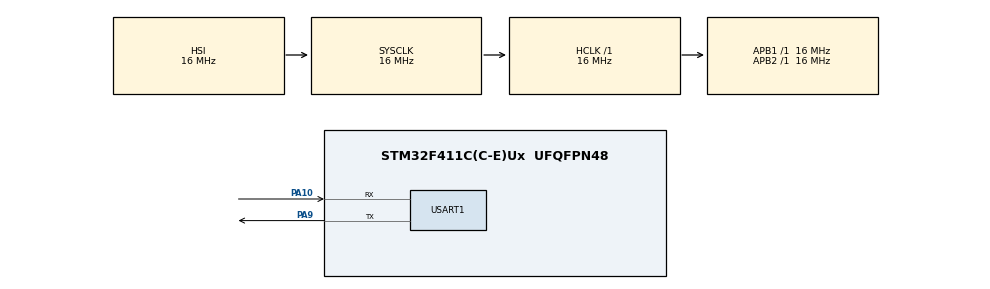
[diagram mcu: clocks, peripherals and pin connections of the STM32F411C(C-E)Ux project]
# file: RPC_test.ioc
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FREERTOS.Tasks01=defaultTask,24,128,StartDefaultTask,Default,NULL,Dynamic,NULL,NULL
Mcu.Family=STM32F4
Mcu.Name=STM32F411C(C-E)Ux
Mcu.Package=UFQFPN48
NVIC.PriorityGroup=NVIC_PRIORITYGROUP_4
NVIC.USART1_IRQn=true\:5\:0\:false\:false\:true\:true\:true\:true\:true
PA10.Mode=Asynchronous
PA10.Signal=USART1_RX
PA13.Mode=Serial_Wire
PA13.Signal=SYS_JTMS-SWDIO
PA14.Mode=Serial_Wire
PA14.Signal=SYS_JTCK-SWCLK
PA9.Mode=Asynchronous
PA9.Signal=USART1_TX
PC14-OSC32_IN.Mode=LSE-External-Oscillator
PC14-OSC32_IN.Signal=RCC_OSC32_IN
PC15-OSC32_OUT.Mode=LSE-External-Oscillator
PC15-OSC32_OUT.Signal=RCC_OSC32_OUT
PH0\ -\ OSC_IN.Mode=HSE-External-Oscillator
PH0\ -\ OSC_IN.Signal=RCC_OSC_IN
PH1\ -\ OSC_OUT.Mode=HSE-External-Oscillator
PH1\ -\ OSC_OUT.Signal=RCC_OSC_OUT
ProjectManager.HeapSize=0x200
ProjectManager.StackSize=0x400
ProjectManager.TargetToolchain=STM32CubeIDE
RCC.AHBFreq_Value=16000000
RCC.APB1Freq_Value=16000000
RCC.APB2Freq_Value=16000000
RCC.CortexFreq_Value=16000000
RCC.HSE_VALUE=25000000
RCC.HSI_VALUE=16000000
RCC.SYSCLKFreq_VALUE=16000000
RCC.VCOOutputFreq_Value=192000000
USART1.VirtualMode=VM_ASYNC
VP_FREERTOS_VS_CMSIS_V2.Mode=CMSIS_V2
board=custom

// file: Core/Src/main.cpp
/* USER CODE BEGIN Header */
/**
  ******************************************************************************
  * @file           : main.c
  * @brief          : Main program body
  ******************************************************************************
  * @attention
  *
  * Copyright (c) 2025 STMicroelectronics.
  * All rights reserved.
  *
  * This software is licensed under terms that can be found in the LICENSE file
  * in the root directory of this software component.
  * If no LICENSE file comes with this software, it is provided AS-IS.
  *
  ******************************************************************************
  */
/* USER CODE END Header */
#include "main.h"
#include "cmsis_os.h"
#include "RPC.h"
#include "stdio.h"
/* USER CODE BEGIN Includes */
class RPC rpc;
/* USER CODE END Includes */

/* USER CODE BEGIN PD */
#ifdef __cplusplus
extern "C" {
#endif

void AddBuffer(uint8_t data)
{
	rpc.AddBuffer(data);
}

#ifdef __cplusplus
}
#endif
/* USER CODE END PD */

UART_HandleTypeDef huart1;

/* Definitions for defaultTask */

void SystemClock_Config(void);
static void MX_GPIO_Init(void);
static void MX_USART1_UART_Init(void);
void StartDefaultTask(void *argument);

/* USER CODE BEGIN PFP */
void Echo(uint8_t* args, size_t argsLength, uint8_t*& response, size_t& responseLength) {
    response = (uint8_t*)pvPortMalloc(argsLength);
    memcpy(response, args, argsLength);
    responseLength = argsLength;
}

void EchoCallback(uint32_t id, uint8_t* data, size_t length, bool success) {
    if (success) printf("Ответ на запрос %lu получен! Длина: %d\n", id, length);
    else 		 printf("Ошибка в запросе %lu\n", id);

}
/* USER CODE END PFP */

int main(void)
{

  /* MCU Configuration--------------------------------------------------------*/

  /* Reset of all peripherals, Initializes the Flash interface and the Systick. */
  HAL_Init();

  /* Configure the system clock */
  SystemClock_Config();

  /* Initialize all configured peripherals */
  MX_GPIO_Init();
  MX_USART1_UART_Init();
  /* USER CODE BEGIN 2 */
  rpc.RegisterFunction("Echo", Echo);
  /* USER CODE END 2 */

  /* Init scheduler */
  osKernelInitialize();

  /* Create the thread(s) */
  /* creation of defaultTask */

  /* USER CODE BEGIN RTOS_THREADS */
  rpc.Start();
  /* USER CODE END RTOS_THREADS */

  uint8_t data[] = {0x01, 0x02, 0x03};

  rpc.SendRequest("Echo", data, sizeof(data), EchoCallback);

  /* Start scheduler */
  osKernelStart();

  /* We should never get here as control is now taken by the scheduler */

  /* Infinite loop */
  while (1)
  {

  }
}

void SystemClock_Config(void)
{
  RCC_OscInitTypeDef RCC_OscInitStruct = {0};
  RCC_ClkInitTypeDef RCC_ClkInitStruct = {0};

  /** Configure the main internal regulator output voltage
  */
  __HAL_RCC_PWR_CLK_ENABLE();
  __HAL_PWR_VOLTAGESCALING_CONFIG(PWR_REGULATOR_VOLTAGE_SCALE1);

  /** Initializes the RCC Oscillators according to the specified parameters
  * in the RCC_OscInitTypeDef structure.
  */
  RCC_OscInitStruct.OscillatorType = RCC_OSCILLATORTYPE_HSI;
  RCC_OscInitStruct.HSIState = RCC_HSI_ON;
  RCC_OscInitStruct.HSICalibrationValue = RCC_HSICALIBRATION_DEFAULT;
  RCC_OscInitStruct.PLL.PLLState = RCC_PLL_NONE;
  if (HAL_RCC_OscConfig(&RCC_OscInitStruct) != HAL_OK)
  {
    Error_Handler();
  }

  /** Initializes the CPU, AHB and APB buses clocks
  */
  RCC_ClkInitStruct.ClockType = RCC_CLOCKTYPE_HCLK|RCC_CLOCKTYPE_SYSCLK
                              |RCC_CLOCKTYPE_PCLK1|RCC_CLOCKTYPE_PCLK2;
  RCC_ClkInitStruct.SYSCLKSource = RCC_SYSCLKSOURCE_HSI;
  RCC_ClkInitStruct.AHBCLKDivider = RCC_SYSCLK_DIV1;
  RCC_ClkInitStruct.APB1CLKDivider = RCC_HCLK_DIV1;
  RCC_ClkInitStruct.APB2CLKDivider = RCC_HCLK_DIV1;

  if (HAL_RCC_ClockConfig(&RCC_ClkInitStruct, FLASH_LATENCY_0) != HAL_OK)
  {
    Error_Handler();
  }
}

static void MX_USART1_UART_Init(void)
{

  huart1.Instance = USART1;
  huart1.Init.BaudRate = 115200;
  huart1.Init.WordLength = UART_WORDLENGTH_8B;
  huart1.Init.StopBits = UART_STOPBITS_1;
  huart1.Init.Parity = UART_PARITY_NONE;
  huart1.Init.Mode = UART_MODE_TX_RX;
  huart1.Init.HwFlowCtl = UART_HWCONTROL_NONE;
  huart1.Init.OverSampling = UART_OVERSAMPLING_16;
  if (HAL_UART_Init(&huart1) != HAL_OK)
  {
    Error_Handler();
  }

}

static void MX_GPIO_Init(void)
{

  /* GPIO Ports Clock Enable */
  __HAL_RCC_GPIOC_CLK_ENABLE();
  __HAL_RCC_GPIOH_CLK_ENABLE();
  __HAL_RCC_GPIOA_CLK_ENABLE();

}

void Error_Handler(void)
{
  __disable_irq();
  while (1)
  {
  }
}
